# Cortex_M4 register map
Vendor: ARM Ltd.; File version: 1.3
Cortex-M4 core descriptions, generated from ARM developer studio
CPU: CM4 r0p0, little endian, MPU, no FPU, vendor SysTick, 8 interrupt priority bits
Registers are 32-bit, read-write, no defined reset value unless marked. A register's access mark holds for its fields unless they carry their own. Offsets are from the block's base; lines under a group give offsets from that group; [hi:lo] are bit positions; {n}, {i} and the like mark numbered series; 'fields as' and 'values as' point back to an identical list; <NAME> marks a mode.

## Memory map
0xE000E008 Control size 0x260 — System Control registers
0xE000E010 SysTick size 0x80 — System Timer registers
0xE000E100 NVIC size 0x3F0 — Nested Vectored Interrupt Controller registers
0xE000ED00 ID size 0x1C0 — ID registers
0xE000ED90 MPU size 0x160 — Memory Protection Unit
0xE000EF00 NVIC_STIR size 0x5 — Nested vectored interrupt controller
0xE000EF34 FPE size 0xA0 — System Control registers for the FP extension

## Control — System Control registers
Base 0xE000E008
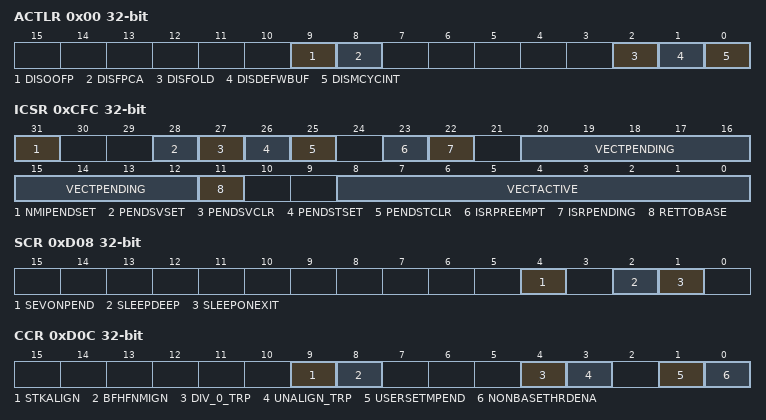
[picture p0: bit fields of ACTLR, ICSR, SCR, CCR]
0x00 ACTLR
  [all] fields
    0=Enabled; 1=Disabled
  [9] DISOOFP
  [8] DISFPCA
  [2] DISFOLD
  [1] DISDEFWBUF
  [0] DISMCYCINT
0xCFC ICSR
  [31] NMIPENDSET
    0=Do_not_activate; 1=Activate_NMI_exception
  [28] PENDSVSET
    0=Do_not_set; 1=Set_pending
  [27] PENDSVCLR
    0=Do_not_clear; 1=Clear_pending
  [26] PENDSTSET
    0=Do_not_set; 1=Set_pending
  [25] PENDSTCLR
    0=Do_not_clear; 1=Clear_pending
  [23] ISRPREEMPT
    0=Will_not_service; 1=Will_service_pending_exception
  [22] ISRPENDING
    0=Interrupt_not_pending; 1=Interrupt_pending
  [20:12] VECTPENDING
  [11] RETTOBASE
    0=Active_exception; 1=No_Active_Exception
  [8:0] VECTACTIVE
0xD00 VTOR
  [29] TBLBASE
    0=CODE; 1=SRAM
  [31:7] TBLOFF
0xD04 AIRCR
  [31:16] VECTKEY
  [31:16] VECTKEYSTAT
  [15] ENDIANNESS
    0=Little_endian; 1=Big_endian
  [10:8] PRIGROUP
  [2] SYSRESETREQ
    0=Do_not_request_reset; 1=Request_reset
  [1] VECTCLRACTIVE
    0=Do_not_clear; 1=Clear_state_information
0xD08 SCR
  [4] SEVONPEND
    0=Not_wakeup; 1=Wakeup
  [2] SLEEPDEEP
    0=Not_deep_sleep; 1=Deep_sleep
  [1] SLEEPONEXIT
    0=Do_not_enter; 1=Enter
0xD0C CCR
  [9] STKALIGN
    0=_4_Byte; 1=_8_Byte
  [8] BFHFNMIGN
    0=Fault; 1=Ignore
  [4] DIV_0_TRP
    0=Disabled; 1=Enabled
  [3] UNALIGN_TRP
    0=Disabled; 1=Enabled
  [1] USERSETMPEND
    0=Disabled; 1=Enabled
  [0] NONBASETHRDENA
    0=Disabled; 1=Enabled
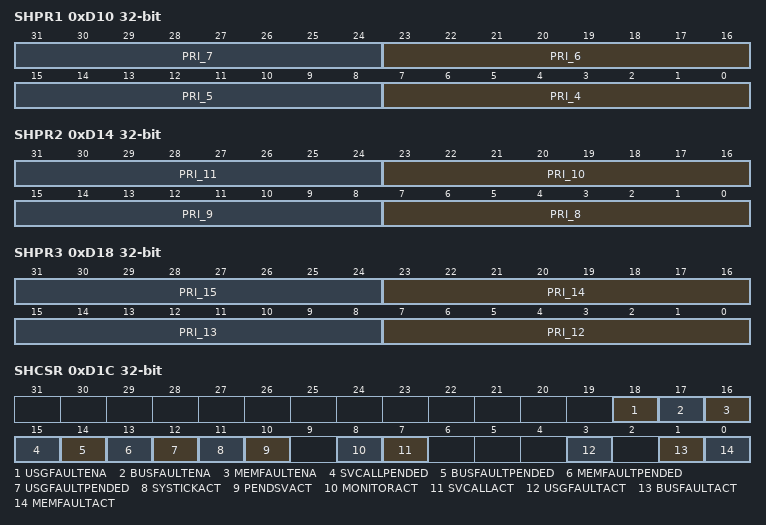
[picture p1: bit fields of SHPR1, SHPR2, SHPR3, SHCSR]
0xD10 SHPR1
  [8n-25:8n-32] PRI_{n} (n=4..7)
0xD14 SHPR2
  [8n-57:8n-64] PRI_{n} (n=8..11)
0xD18 SHPR3
  [8n-89:8n-96] PRI_{n} (n=12..15)
0xD1C SHCSR
  [18] USGFAULTENA
    0=Disabled; 1=Enabled
  [17] BUSFAULTENA
    0=Disabled; 1=Enabled
  [16] MEMFAULTENA
    0=Disabled; 1=Enabled
  [15] SVCALLPENDED
    0=Not_pending; 1=Pending
  [14] BUSFAULTPENDED
    0=Not_pending; 1=Pending
  [13] MEMFAULTPENDED
    0=Not_pending; 1=Pending
  [12] USGFAULTPENDED
    0=Not_pending; 1=Pending
  [11] SYSTICKACT
    0=Not_active; 1=Active
  [10] PENDSVACT
    0=Not_active; 1=Active
  [8] MONITORACT
    0=Not_active; 1=Active
  [7] SVCALLACT
    0=Not_active; 1=Active
  [3] USGFAULTACT
    0=Not_active; 1=Active
  [1] BUSFAULTACT
    0=Not_active; 1=Active
  [0] MEMFAULTACT
    0=Not_active; 1=Active
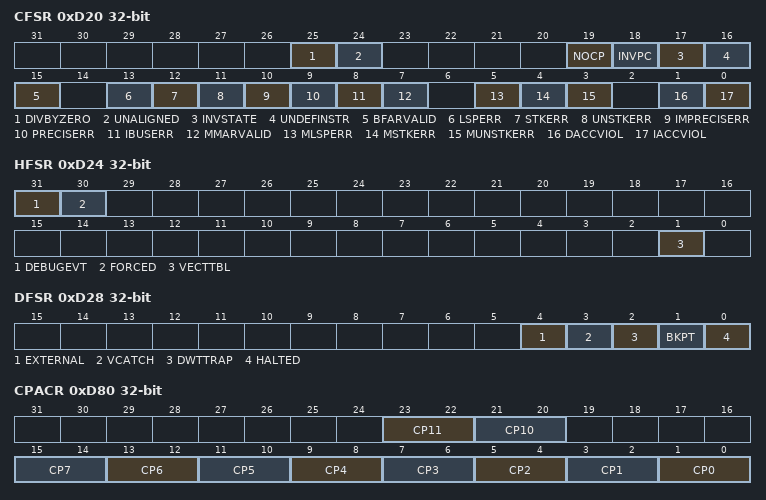
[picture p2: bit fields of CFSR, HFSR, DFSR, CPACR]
0xD20 CFSR
  [25] DIVBYZERO
    0=Not_occurred; 1=Occurred
  [24] UNALIGNED
    0=Not_occurred; 1=Occurred
  [19] NOCP
    0=Not_occurred; 1=Occurred
  [18] INVPC
    0=Not_occurred; 1=Occurred
  [17] INVSTATE
    0=Not_occurred; 1=Occurred
  [16] UNDEFINSTR
    0=Not_occurred; 1=Occurred
  [15] BFARVALID
    0=Not_valid; 1=Valid
  [13] LSPERR
    0=Not_occurred; 1=Occurred
  [12] STKERR
    0=Not_occurred; 1=Occurred
  [11] UNSTKERR
    0=Not_occurred; 1=Occurred
  [10] IMPRECISERR
    0=Not_occurred; 1=Occurred
  [9] PRECISERR
    0=Not_occurred; 1=Occurred
  [8] IBUSERR
    0=Not_occurred; 1=Occurred
  [7] MMARVALID
    0=Not_valid; 1=Valid
  [5] MLSPERR
    0=Not_occurred; 1=Occurred
  [4] MSTKERR
    0=Not_occurred; 1=Occurred
  [3] MUNSTKERR
    0=Not_occurred; 1=Occurred
  [1] DACCVIOL
    0=Not_occurred; 1=Occurred
  [0] IACCVIOL
    0=Not_occurred; 1=Occurred
0xD24 HFSR
  [all] fields
    0=Not_occurred; 1=Occurred
  [31] DEBUGEVT
  [30] FORCED
  [1] VECTTBL
0xD28 DFSR
  [4] EXTERNAL, [3] VCATCH, [2] DWTTRAP, [1] BKPT, [0] HALTED
0xD2C MMFAR
0xD30 BFAR
0xD34 AFSR
0xD80 CPACR
  [all] fields
    0=Access_denied; 1=Privileged_mode_access_only; 3=Full_access
  [23:22] CP11
  [21:20] CP10
  [2n+1:2n] CP{n} (n=0..7)
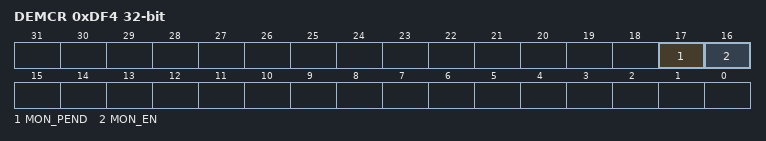
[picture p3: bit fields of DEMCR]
0xDF4 DEMCR ro
  [17] MON_PEND, [16] MON_EN
0xEF8 STIR wo
  [8:0] INTID

## Notices in the file
Copyright (c) 2025 STMicroelectronics.
SPDX-License-Identifier: Apache-2.0
Licensed under the Apache License, Version 2.0 (the "License");
you may not use this file except in compliance with the License.
You may obtain a copy of the License at
http://www.apache.org/licenses/LICENSE-2.0
Unless required by applicable law or agreed to in writing, software
distributed under the License is distributed on an "AS IS" BASIS,
WITHOUT WARRANTIES OR CONDITIONS OF ANY KIND, either express or implied.
See the License for the specific language governing permissions and
limitations under the License.
